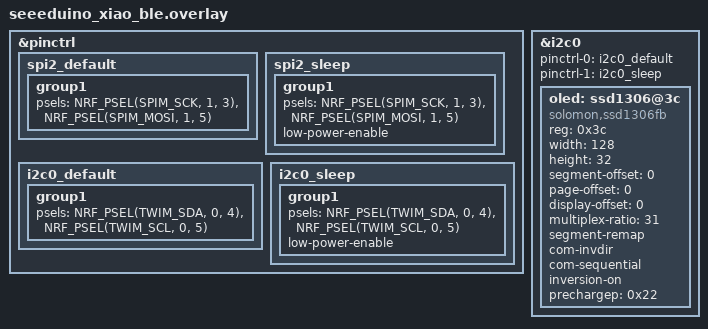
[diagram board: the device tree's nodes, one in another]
&pinctrl {
    spi2_default: spi2_default {
        group1 {
            psels = <NRF_PSEL(SPIM_SCK, 1, 3)>,
                    <NRF_PSEL(SPIM_MOSI, 1, 5)>;
        };
    };

    spi2_sleep: spi2_sleep {
        group1 {
            psels = <NRF_PSEL(SPIM_SCK, 1, 3)>,
                    <NRF_PSEL(SPIM_MOSI, 1, 5)>;
            low-power-enable;
        };
    };

    i2c0_default: i2c0_default {
        group1 {
            psels = <NRF_PSEL(TWIM_SDA, 0, 4)>,
                    <NRF_PSEL(TWIM_SCL, 0, 5)>;
        };
    };

    i2c0_sleep: i2c0_sleep {
        group1 {
            psels = <NRF_PSEL(TWIM_SDA, 0, 4)>,
                    <NRF_PSEL(TWIM_SCL, 0, 5)>;
            low-power-enable;
        };
    };
};

/* Variant C: use nrf-twi (not twim) to match board DTS default */
&i2c0 {
    status = "okay";
    pinctrl-0 = <&i2c0_default>;
    pinctrl-1 = <&i2c0_sleep>;
    pinctrl-names = "default", "sleep";

    oled: ssd1306@3c {
        compatible = "solomon,ssd1306fb";
        reg = <0x3c>;
        width = <128>;
        height = <32>;
        segment-offset = <0>;
        page-offset = <0>;
        display-offset = <0>;
        multiplex-ratio = <31>;
        segment-remap;
        com-invdir;
        com-sequential;
        inversion-on;
        prechargep = <0x22>;
    };
};
